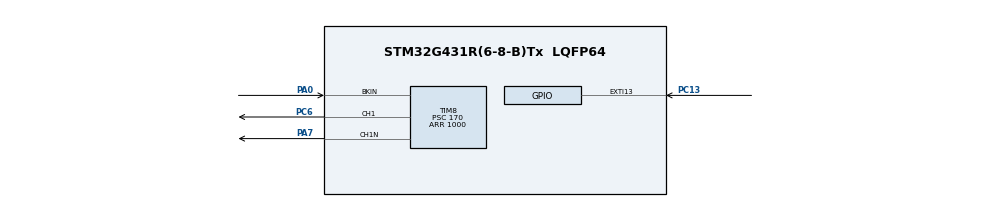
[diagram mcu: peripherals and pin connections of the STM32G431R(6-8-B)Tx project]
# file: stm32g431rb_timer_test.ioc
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Mcu.Family=STM32G4
Mcu.Name=STM32G431R(6-8-B)Tx
Mcu.Package=LQFP64
NVIC.EXTI15_10_IRQn=true\:0\:0\:false\:false\:true\:true\:true\:true
NVIC.PriorityGroup=NVIC_PRIORITYGROUP_4
PA0.Mode=Activate-Break-Input
PA0.Signal=TIM8_BKIN
PA7.Mode=PWM Generation1 CH1 CH1N
PA7.Signal=TIM8_CH1N
PC13.Signal=GPXTI13
PC6.Signal=S_TIM8_CH1
ProjectManager.HeapSize=0x200
ProjectManager.StackSize=0x400
ProjectManager.TargetToolchain=STM32CubeIDE
RCC.ADC12Freq_Value=170000000
RCC.AHBFreq_Value=170000000
RCC.APB1Freq_Value=170000000
RCC.APB1TimFreq_Value=170000000
RCC.APB2Freq_Value=170000000
RCC.APB2TimFreq_Value=170000000
RCC.CortexFreq_Value=170000000
RCC.EXTERNAL_CLOCK_VALUE=12288000
RCC.HCLKFreq_Value=170000000
RCC.HSE_VALUE=8000000
RCC.HSI48_VALUE=48000000
RCC.HSI_VALUE=16000000
RCC.LSE_VALUE=32768
RCC.PLLM=RCC_PLLM_DIV4
RCC.PLLN=85
RCC.SYSCLKFreq_VALUE=170000000
RCC.SYSCLKSource=RCC_SYSCLKSOURCE_PLLCLK
RCC.USBFreq_Value=170000000
RCC.VCOOutputFreq_Value=340000000
SH.S_TIM8_CH1.0=TIM8_CH1,PWM Generation1 CH1 CH1N
TIM8.AutomaticOutput=TIM_AUTOMATICOUTPUT_DISABLE
TIM8.BreakState=TIM_BREAK_ENABLE
TIM8.Channel-PWM\ Generation1\ CH1\ CH1N=TIM_CHANNEL_1
TIM8.CounterMode=TIM_COUNTERMODE_CENTERALIGNED1
TIM8.DeadTime=100
TIM8.OCIdleState_1=TIM_OCIDLESTATE_SET
TIM8.OCMode_PWM-PWM\ Generation1\ CH1\ CH1N=TIM_OCMODE_PWM1
TIM8.OCNPolarity_1=TIM_OCNPOLARITY_HIGH
TIM8.OCPolarity_1=TIM_OCPOLARITY_LOW
TIM8.OffStateIDLEMode=TIM_OSSI_ENABLE
TIM8.OffStateRunMode=TIM_OSSR_ENABLE
TIM8.PeriodNoDither=1000
TIM8.Prescaler=170
TIM8.PulseNoDither_1=750
VP_SYS_VS_DBSignals.Mode=DisableDeadBatterySignals
board=custom

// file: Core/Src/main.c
/* USER CODE BEGIN Header */
/**
  ******************************************************************************
  * @file           : main.c
  * @brief          : Main program body
  ******************************************************************************
  * @attention
  *
  * Copyright (c) 2024 STMicroelectronics.
  * All rights reserved.
  *
  * This software is licensed under terms that can be found in the LICENSE file
  * in the root directory of this software component.
  * If no LICENSE file comes with this software, it is provided AS-IS.
  *
  ******************************************************************************
  */
/* USER CODE END Header */
#include "main.h"

void SystemClock_Config(void);
static void MX_GPIO_Init(void);
static void MX_TIM8_Init(void);

/* USER CODE BEGIN 0 */
void HAL_GPIO_EXTI_Callback(uint16_t GPIO_Pin)
{
  if(LL_TIM_IsEnabledAllOutputs(TIM8) == 1)
  {
    LL_TIM_DisableAllOutputs(TIM8);
  }
  else
  {
    LL_TIM_EnableAllOutputs(TIM8);
  }
}
/* USER CODE END 0 */

int main(void)
{

  /* MCU Configuration--------------------------------------------------------*/

  /* Reset of all peripherals, Initializes the Flash interface and the Systick. */
  HAL_Init();

  /* Configure the system clock */
  SystemClock_Config();

  /* Initialize all configured peripherals */
  MX_GPIO_Init();
  MX_TIM8_Init();
  /* USER CODE BEGIN 2 */
  LL_TIM_CC_EnableChannel(TIM8, LL_TIM_CHANNEL_CH1);
  LL_TIM_CC_EnableChannel(TIM8, LL_TIM_CHANNEL_CH1N);

  LL_TIM_EnableAllOutputs(TIM8);
  LL_TIM_EnableCounter(TIM8);
  /* USER CODE END 2 */

  /* Infinite loop */
  while (1)
  {

  }
}

void SystemClock_Config(void)
{
  LL_FLASH_SetLatency(LL_FLASH_LATENCY_4);
  while(LL_FLASH_GetLatency() != LL_FLASH_LATENCY_4)
  {
  }
  LL_PWR_EnableRange1BoostMode();
  LL_RCC_HSI_Enable();
   /* Wait till HSI is ready */
  while(LL_RCC_HSI_IsReady() != 1)
  {
  }

  LL_RCC_HSI_SetCalibTrimming(64);
  LL_RCC_PLL_ConfigDomain_SYS(LL_RCC_PLLSOURCE_HSI, LL_RCC_PLLM_DIV_4, 85, LL_RCC_PLLR_DIV_2);
  LL_RCC_PLL_EnableDomain_SYS();
  LL_RCC_PLL_Enable();
   /* Wait till PLL is ready */
  while(LL_RCC_PLL_IsReady() != 1)
  {
  }

  LL_RCC_SetSysClkSource(LL_RCC_SYS_CLKSOURCE_PLL);
  LL_RCC_SetAHBPrescaler(LL_RCC_SYSCLK_DIV_2);
   /* Wait till System clock is ready */
  while(LL_RCC_GetSysClkSource() != LL_RCC_SYS_CLKSOURCE_STATUS_PLL)
  {
  }

  /* Insure 1us transition state at intermediate medium speed clock*/
  for (__IO uint32_t i = (170 >> 1); i !=0; i--);

  /* Set AHB prescaler*/
  LL_RCC_SetAHBPrescaler(LL_RCC_SYSCLK_DIV_1);
  LL_RCC_SetAPB1Prescaler(LL_RCC_APB1_DIV_1);
  LL_RCC_SetAPB2Prescaler(LL_RCC_APB2_DIV_1);
  LL_SetSystemCoreClock(170000000);

   /* Update the time base */
  if (HAL_InitTick (TICK_INT_PRIORITY) != HAL_OK)
  {
    Error_Handler();
  }
}

static void MX_TIM8_Init(void)
{

  LL_TIM_InitTypeDef TIM_InitStruct = {0};
  LL_TIM_OC_InitTypeDef TIM_OC_InitStruct = {0};
  LL_TIM_BDTR_InitTypeDef TIM_BDTRInitStruct = {0};

  LL_GPIO_InitTypeDef GPIO_InitStruct = {0};

  /* Peripheral clock enable */
  LL_APB2_GRP1_EnableClock(LL_APB2_GRP1_PERIPH_TIM8);

  LL_AHB2_GRP1_EnableClock(LL_AHB2_GRP1_PERIPH_GPIOA);
  /**TIM8 GPIO Configuration
  PA0   ------> TIM8_BKIN
  */
  GPIO_InitStruct.Pin = LL_GPIO_PIN_0;
  GPIO_InitStruct.Mode = LL_GPIO_MODE_ALTERNATE;
  GPIO_InitStruct.Speed = LL_GPIO_SPEED_FREQ_LOW;
  GPIO_InitStruct.OutputType = LL_GPIO_OUTPUT_OPENDRAIN;
  GPIO_InitStruct.Pull = LL_GPIO_PULL_NO;
  GPIO_InitStruct.Alternate = LL_GPIO_AF_9;
  LL_GPIO_Init(GPIOA, &GPIO_InitStruct);

  TIM_InitStruct.Prescaler = 170;
  TIM_InitStruct.CounterMode = LL_TIM_COUNTERMODE_CENTER_DOWN;
  TIM_InitStruct.Autoreload = 1000;
  TIM_InitStruct.ClockDivision = LL_TIM_CLOCKDIVISION_DIV1;
  TIM_InitStruct.RepetitionCounter = 0;
  LL_TIM_Init(TIM8, &TIM_InitStruct);
  LL_TIM_DisableARRPreload(TIM8);
  LL_TIM_OC_EnablePreload(TIM8, LL_TIM_CHANNEL_CH1);
  TIM_OC_InitStruct.OCMode = LL_TIM_OCMODE_PWM1;
  TIM_OC_InitStruct.OCState = LL_TIM_OCSTATE_DISABLE;
  TIM_OC_InitStruct.OCNState = LL_TIM_OCSTATE_DISABLE;
  TIM_OC_InitStruct.CompareValue = 750;
  TIM_OC_InitStruct.OCPolarity = LL_TIM_OCPOLARITY_LOW;
  TIM_OC_InitStruct.OCNPolarity = LL_TIM_OCPOLARITY_HIGH;
  TIM_OC_InitStruct.OCIdleState = LL_TIM_OCIDLESTATE_HIGH;
  TIM_OC_InitStruct.OCNIdleState = LL_TIM_OCIDLESTATE_LOW;
  LL_TIM_OC_Init(TIM8, LL_TIM_CHANNEL_CH1, &TIM_OC_InitStruct);
  LL_TIM_OC_DisableFast(TIM8, LL_TIM_CHANNEL_CH1);
  LL_TIM_SetTriggerOutput(TIM8, LL_TIM_TRGO_RESET);
  LL_TIM_SetTriggerOutput2(TIM8, LL_TIM_TRGO2_RESET);
  LL_TIM_DisableMasterSlaveMode(TIM8);
  LL_TIM_SetBreakInputSourcePolarity(TIM8, LL_TIM_BREAK_INPUT_BKIN, LL_TIM_BKIN_SOURCE_BKIN, LL_TIM_BKIN_POLARITY_HIGH);
  TIM_BDTRInitStruct.OSSRState = LL_TIM_OSSR_ENABLE;
  TIM_BDTRInitStruct.OSSIState = LL_TIM_OSSI_ENABLE;
  TIM_BDTRInitStruct.LockLevel = LL_TIM_LOCKLEVEL_OFF;
  TIM_BDTRInitStruct.DeadTime = 100;
  TIM_BDTRInitStruct.BreakState = LL_TIM_BREAK_ENABLE;
  TIM_BDTRInitStruct.BreakPolarity = LL_TIM_BREAK_POLARITY_HIGH;
  TIM_BDTRInitStruct.BreakFilter = LL_TIM_BREAK_FILTER_FDIV1;
  TIM_BDTRInitStruct.BreakAFMode = LL_TIM_BREAK_AFMODE_INPUT;
  TIM_BDTRInitStruct.Break2State = LL_TIM_BREAK2_DISABLE;
  TIM_BDTRInitStruct.Break2Polarity = LL_TIM_BREAK2_POLARITY_HIGH;
  TIM_BDTRInitStruct.Break2Filter = LL_TIM_BREAK2_FILTER_FDIV1;
  TIM_BDTRInitStruct.Break2AFMode = LL_TIM_BREAK_AFMODE_INPUT;
  TIM_BDTRInitStruct.AutomaticOutput = LL_TIM_AUTOMATICOUTPUT_DISABLE;
  LL_TIM_BDTR_Init(TIM8, &TIM_BDTRInitStruct);
  LL_AHB2_GRP1_EnableClock(LL_AHB2_GRP1_PERIPH_GPIOA);
  LL_AHB2_GRP1_EnableClock(LL_AHB2_GRP1_PERIPH_GPIOC);
  /**TIM8 GPIO Configuration
  PA7   ------> TIM8_CH1N
  PC6   ------> TIM8_CH1
  */
  GPIO_InitStruct.Pin = LL_GPIO_PIN_7;
  GPIO_InitStruct.Mode = LL_GPIO_MODE_ALTERNATE;
  GPIO_InitStruct.Speed = LL_GPIO_SPEED_FREQ_LOW;
  GPIO_InitStruct.OutputType = LL_GPIO_OUTPUT_PUSHPULL;
  GPIO_InitStruct.Pull = LL_GPIO_PULL_NO;
  GPIO_InitStruct.Alternate = LL_GPIO_AF_4;
  LL_GPIO_Init(GPIOA, &GPIO_InitStruct);

  GPIO_InitStruct.Pin = LL_GPIO_PIN_6;
  GPIO_InitStruct.Mode = LL_GPIO_MODE_ALTERNATE;
  GPIO_InitStruct.Speed = LL_GPIO_SPEED_FREQ_LOW;
  GPIO_InitStruct.OutputType = LL_GPIO_OUTPUT_PUSHPULL;
  GPIO_InitStruct.Pull = LL_GPIO_PULL_NO;
  GPIO_InitStruct.Alternate = LL_GPIO_AF_4;
  LL_GPIO_Init(GPIOC, &GPIO_InitStruct);

}

static void MX_GPIO_Init(void)
{
  GPIO_InitTypeDef GPIO_InitStruct = {0};

  /* GPIO Ports Clock Enable */
  __HAL_RCC_GPIOC_CLK_ENABLE();
  __HAL_RCC_GPIOA_CLK_ENABLE();

  /*Configure GPIO pin : PC13 */
  GPIO_InitStruct.Pin = GPIO_PIN_13;
  GPIO_InitStruct.Mode = GPIO_MODE_IT_RISING;
  GPIO_InitStruct.Pull = GPIO_NOPULL;
  HAL_GPIO_Init(GPIOC, &GPIO_InitStruct);

  /* EXTI interrupt init*/
  HAL_NVIC_SetPriority(EXTI15_10_IRQn, 0, 0);
  HAL_NVIC_EnableIRQ(EXTI15_10_IRQn);

}

void Error_Handler(void)
{
  __disable_irq();
  while (1)
  {
  }
}
